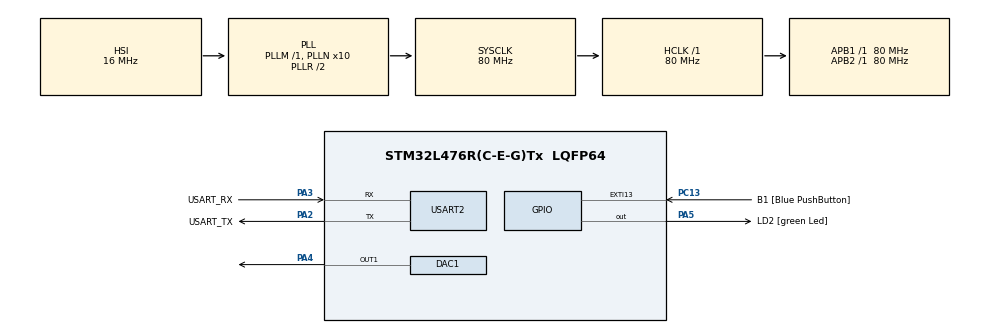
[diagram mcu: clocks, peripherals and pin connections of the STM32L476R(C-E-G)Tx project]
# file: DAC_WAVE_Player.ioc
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Mcu.Family=STM32L4
PA2.GPIO_PuPd=GPIO_NOPULL
RCC.CortexFreq_Value=80000000
PH0-OSC_IN\ (PH0).Signal=RCC_OSC_IN
PA3.GPIO_PuPd=GPIO_NOPULL
PA2.GPIO_Speed=GPIO_SPEED_FREQ_VERY_HIGH
PC15-OSC32_OUT\ (PC15).Mode=LSE-External-Oscillator
PC13.GPIO_Label=B1 [Blue PushButton]
PA3.GPIO_Speed=GPIO_SPEED_FREQ_VERY_HIGH
RCC.SYSCLKSource=RCC_SYSCLKSOURCE_PLLCLK
ProjectManager.StackSize=0x400
PB3\ (JTDO-TRACESWO).Signal=SYS_JTDO-SWO
PC14-OSC32_IN\ (PC14).Mode=LSE-External-Oscillator
NVIC.DMA1_Channel3_IRQn=true\:0\:0\:false\:false\:true\:false\:true
PA14\ (JTCK-SWCLK).Signal=SYS_JTCK-SWCLK
Dma.DAC_CH1.0.Instance=DMA1_Channel3
RCC.HCLKFreq_Value=80000000
RCC.APB2TimFreq_Value=80000000
RCC.AHBFreq_Value=80000000
RCC.PREFETCH_ENABLE=1
RCC.HSE_VALUE=8000000
USART2.VirtualMode-Asynchronous=VM_ASYNC
PA5.GPIO_PuPd=GPIO_NOPULL
PC13.GPIO_PuPd=GPIO_NOPULL
Dma.DAC_CH1.0.PeriphDataAlignment=DMA_PDATAALIGN_HALFWORD
Mcu.Package=LQFP64
PA2.GPIO_Label=USART_TX
Dma.DAC_CH1.0.Priority=DMA_PRIORITY_LOW
RCC.APB1TimFreq_Value=80000000
PA13\ (JTMS-SWDIO).Signal=SYS_JTMS-SWDIO
Dma.Request0=DAC_CH1
PA3.Signal=USART2_RX
PA2.GPIO_Mode=GPIO_MODE_AF_PP
RCC.MSI_VALUE=4000000
RCC.PLLSourceVirtual=RCC_PLLSOURCE_HSI
PA14\ (JTCK-SWCLK).Mode=Serial_Wire
Dma.DAC_CH1.0.Mode=DMA_NORMAL
Dma.DAC_CH1.0.MemDataAlignment=DMA_MDATAALIGN_HALFWORD
PC13.Signal=GPXTI13
TIM6.Prescaler=0
VP_TIM6_VS_ClockSourceINT.Mode=Enable_Timer
PC15-OSC32_OUT\ (PC15).Signal=RCC_OSC32_OUT
PA14\ (JTCK-SWCLK).GPIO_Label=TCK
PB3\ (JTDO-TRACESWO).GPIO_Label=SWO
PH1-OSC_OUT\ (PH1).Signal=RCC_OSC_OUT
PA3.Mode=Asynchronous
Dma.DAC_CH1.0.Direction=DMA_MEMORY_TO_PERIPH
ProjectManager.TargetToolchain=STM32CubeIDE
PA3.GPIO_Mode=GPIO_MODE_AF_PP
SH.COMP_DAC11_group.0=DAC1_OUT1,DAC_OUT1
Dma.DAC_CH1.0.MemInc=DMA_MINC_ENABLE
RCC.USBFreq_Value=64000000
PA5.Signal=GPIO_Output
board=NUCLEO-L476RG
RCC.VCOOutputFreq_Value=160000000
RCC.APB2Freq_Value=80000000
PA5.GPIO_ModeDefaultOutputPP=GPIO_MODE_OUTPUT_PP
PA13\ (JTMS-SWDIO).GPIO_Label=TMS
RCC.ADCFreq_Value=64000000
TIM6.TIM_MasterOutputTrigger=TIM_TRGO_UPDATE
DAC1.DAC_Trigger-DAC_OUT1=DAC_TRIGGER_T6_TRGO
Mcu.Name=STM32L476R(C-E-G)Tx
PA2.Signal=USART2_TX
PA13\ (JTMS-SWDIO).Mode=Serial_Wire
Dma.DAC_CH1.0.PeriphInc=DMA_PINC_DISABLE
PA4.Signal=COMP_DAC11_group
RCC.SYSCLKFreq_VALUE=80000000
PA5.GPIO_Label=LD2 [green Led]
PC13.GPIO_ModeDefaultEXTI=GPIO_MODE_IT_FALLING
PC14-OSC32_IN\ (PC14).Signal=RCC_OSC32_IN
ProjectManager.HeapSize=0x200
RCC.HSI_VALUE=16000000
PA5.GPIO_Speed=GPIO_SPEED_FREQ_LOW
NVIC.PriorityGroup=NVIC_PRIORITYGROUP_4
RCC.PLLN=10
PA2.Mode=Asynchronous
RCC.APB1Freq_Value=80000000
PA3.GPIO_Label=USART_RX

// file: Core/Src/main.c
/* USER CODE BEGIN Header */
/**
  ******************************************************************************
  * @file           : main.c
  * @brief          : Main program body
  ******************************************************************************
  * @attention
  *
  * <h2><center>&copy; Copyright (c) 2021 STMicroelectronics.
  * All rights reserved.</center></h2>
  *
  * This software component is licensed by ST under BSD 3-Clause license,
  * the "License"; You may not use this file except in compliance with the
  * License. You may obtain a copy of the License at:
  *                        opensource.org/licenses/BSD-3-Clause
  *
  ******************************************************************************
  */
/* USER CODE END Header */
#include "main.h"
#include "dac.h"
#include "dma.h"
#include "tim.h"
#include "usart.h"
#include "gpio.h"

/* USER CODE BEGIN PV */
extern uint8_t audio_file[];
/* USER CODE END PV */

void SystemClock_Config(void);

int main(void)
{

  /* MCU Configuration--------------------------------------------------------*/

  /* Reset of all peripherals, Initializes the Flash interface and the Systick. */
  HAL_Init();

  /* Configure the system clock */
  SystemClock_Config();

  /* Initialize all configured peripherals */
  MX_GPIO_Init();
  MX_DMA_Init();
  MX_USART2_UART_Init();
  MX_DAC1_Init();
  MX_TIM6_Init();
  /* USER CODE BEGIN 2 */
  wave_player_init(&htim6, &hdac1);
  wave_player_start(audio_file);
  /* USER CODE END 2 */

  /* Infinite loop */
  while (1)
  {

  }
}

void SystemClock_Config(void)
{
  RCC_OscInitTypeDef RCC_OscInitStruct = {0};
  RCC_ClkInitTypeDef RCC_ClkInitStruct = {0};
  RCC_PeriphCLKInitTypeDef PeriphClkInit = {0};

  /** Initializes the RCC Oscillators according to the specified parameters
  * in the RCC_OscInitTypeDef structure.
  */
  RCC_OscInitStruct.OscillatorType = RCC_OSCILLATORTYPE_HSI;
  RCC_OscInitStruct.HSIState = RCC_HSI_ON;
  RCC_OscInitStruct.HSICalibrationValue = RCC_HSICALIBRATION_DEFAULT;
  RCC_OscInitStruct.PLL.PLLState = RCC_PLL_ON;
  RCC_OscInitStruct.PLL.PLLSource = RCC_PLLSOURCE_HSI;
  RCC_OscInitStruct.PLL.PLLM = 1;
  RCC_OscInitStruct.PLL.PLLN = 10;
  RCC_OscInitStruct.PLL.PLLP = RCC_PLLP_DIV7;
  RCC_OscInitStruct.PLL.PLLQ = RCC_PLLQ_DIV2;
  RCC_OscInitStruct.PLL.PLLR = RCC_PLLR_DIV2;
  if (HAL_RCC_OscConfig(&RCC_OscInitStruct) != HAL_OK)
  {
    Error_Handler();
  }
  /** Initializes the CPU, AHB and APB buses clocks
  */
  RCC_ClkInitStruct.ClockType = RCC_CLOCKTYPE_HCLK|RCC_CLOCKTYPE_SYSCLK
                              |RCC_CLOCKTYPE_PCLK1|RCC_CLOCKTYPE_PCLK2;
  RCC_ClkInitStruct.SYSCLKSource = RCC_SYSCLKSOURCE_PLLCLK;
  RCC_ClkInitStruct.AHBCLKDivider = RCC_SYSCLK_DIV1;
  RCC_ClkInitStruct.APB1CLKDivider = RCC_HCLK_DIV1;
  RCC_ClkInitStruct.APB2CLKDivider = RCC_HCLK_DIV1;

  if (HAL_RCC_ClockConfig(&RCC_ClkInitStruct, FLASH_LATENCY_4) != HAL_OK)
  {
    Error_Handler();
  }
  PeriphClkInit.PeriphClockSelection = RCC_PERIPHCLK_USART2;
  PeriphClkInit.Usart2ClockSelection = RCC_USART2CLKSOURCE_PCLK1;
  if (HAL_RCCEx_PeriphCLKConfig(&PeriphClkInit) != HAL_OK)
  {
    Error_Handler();
  }
  /** Configure the main internal regulator output voltage
  */
  if (HAL_PWREx_ControlVoltageScaling(PWR_REGULATOR_VOLTAGE_SCALE1) != HAL_OK)
  {
    Error_Handler();
  }
}

/* USER CODE BEGIN 4 */
void HAL_DAC_ConvCpltCallbackCh1(DAC_HandleTypeDef *hdac)
{
	wave_player_prepare_half_buffer(SECOND_HALF_OF_BUFFER);
}

void HAL_DAC_ConvHalfCpltCallbackCh1(DAC_HandleTypeDef *hdac)
{
	wave_player_prepare_half_buffer(FIRST_HALF_OF_BUFFER);
}
/* USER CODE END 4 */

void Error_Handler(void)
{
  __disable_irq();
  while (1)
  {
  }
}

/************************ (C) COPYRIGHT STMicroelectronics *****END OF FILE****/
